# MSP430G2X52 register map
Vendor: msp430gen; File version: v0.4.0-16-g4f822b9
Registers are 8-bit, read-write, reset 0x0 unless marked. A register's access mark holds for its fields unless they carry their own. Offsets are from the block's base; lines under a group give offsets from that group; [hi:lo] are bit positions; {n}, {i} and the like mark numbered series; 'fields as' and 'values as' point back to an identical list; <NAME> marks a mode.

## Memory map
0x00000000 SPECIAL_FUNCTION
0x00000020 PORT_1_2
0x00000048 ADC10
0x00000052 SYSTEM_CLOCK
0x00000058 COMPARATOR_A
0x00000078 USI
0x00000120 WATCHDOG_TIMER
0x00000128 FLASH
0x0000012E TIMER0_A3 — Timer A3
0x000010C0 TLV_CALIBRATION_DATA
0x000010F8 CALIBRATION_DATA
0x0000FFE0 _INTERRUPTS

## Interrupts
2 PORT1 (_INTERRUPTS) — 0xFFE4 Port 1
3 PORT2 (_INTERRUPTS) — 0xFFE6 Port 2
4 USI (_INTERRUPTS) — 0xFFE8 USI
5 ADC10 (_INTERRUPTS) — 0xFFEA ADC10
8 TIMER0_A1 (_INTERRUPTS) — 0xFFF0 Timer0_A CC1, TA
9 TIMER0_A0 (_INTERRUPTS) — 0xFFF2 Timer0_A CC0
10 WDT (_INTERRUPTS) — 0xFFF4 Watchdog Timer
11 COMPARATORA (_INTERRUPTS) — 0xFFF6 Comparator A
14 NMI (_INTERRUPTS) — 0xFFFC Non-maskable

## SPECIAL_FUNCTION
Base 0x00000000
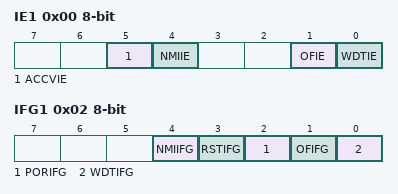
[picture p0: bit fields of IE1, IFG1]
0x00 IE1 — Interrupt Enable 1
  [5] ACCVIE — Flash Access Violation Interrupt Enable
  [4] NMIIE — NMI Interrupt Enable
  [1] OFIE — Osc. Fault Interrupt Enable
  [0] WDTIE — Watchdog Interrupt Enable
0x02 IFG1 — Interrupt Flag 1
  [4] NMIIFG — NMI Interrupt Flag
  [3] RSTIFG — Reset Interrupt Flag
  [2] PORIFG — Power On Interrupt Flag
  [1] OFIFG — Osc. Fault Interrupt Flag
  [0] WDTIFG — Watchdog Interrupt Flag

## PORT_1_2
Base 0x00000020
0x00 P1IN — Port 1 Input
  [n] P{n} (n=0..7)
  [7:0] P1IN — Port 1 Input register
0x01 P1OUT — Port 1 Output
  [n] P{n} (n=0..7)
  [7:0] P1OUT — Port 1 Output register
0x02 P1DIR — Port 1 Direction
  [n] P{n} (n=0..7)
  [7:0] P1DIR — Port 1 Direction register
0x03 P1IFG — Port 1 Interrupt Flag
  [n] P{n} (n=0..7)
  [7:0] P1IFG — Port 1 Interrupt Flag register
0x04 P1IES — Port 1 Interrupt Edge Select
  [n] P{n} (n=0..7)
  [7:0] P1IES — Port 1 Interrupt Edge Select register
0x05 P1IE — Port 1 Interrupt Enable
  [n] P{n} (n=0..7)
  [7:0] P1IE — Port 1 Interrupt Enable register
0x06 P1SEL — Port 1 Selection
  [n] P{n} (n=0..7)
  [7:0] P1SEL — Port 1 Selection register
0x07 P1REN — Port 1 Resistor Enable
  [n] P{n} (n=0..7)
  [7:0] P1REN — Port 1 Resistor Enable register
0x08 P2IN — Port 2 Input
  [n] P{n} (n=0..7)
  [7:0] P2IN — Port 2 Input register
0x09 P2OUT — Port 2 Output
  [n] P{n} (n=0..7)
  [7:0] P2OUT — Port 2 Output register
0x0A P2DIR — Port 2 Direction
  [n] P{n} (n=0..7)
  [7:0] P2DIR — Port 2 Direction register
0x0B P2IFG — Port 2 Interrupt Flag
  [n] P{n} (n=0..7)
  [7:0] P2IFG — Port 2 Interrupt Flag register
0x0C P2IES — Port 2 Interrupt Edge Select
  [n] P{n} (n=0..7)
  [7:0] P2IES — Port 2 Interrupt Edge Select register
0x0D P2IE — Port 2 Interrupt Enable
  [n] P{n} (n=0..7)
  [7:0] P2IE — Port 2 Interrupt Enable register
0x0E P2SEL — Port 2 Selection
  [n] P{n} (n=0..7)
  [7:0] P2SEL — Port 2 Selection register
0x0F P2REN — Port 2 Resistor Enable
  [n] P{n} (n=0..7)
  [7:0] P2REN — Port 2 Resistor Enable register
0x21 P1SEL2 — Port 1 Selection 2
  [n] P{n} (n=0..7)
  [7:0] P1SEL2 — Port 1 Selection register 2
0x22 P2SEL2 — Port 2 Selection 2
  [n] P{n} (n=0..7)
  [7:0] P2SEL2 — Port 2 Selection register 2

## ADC10
Base 0x00000048
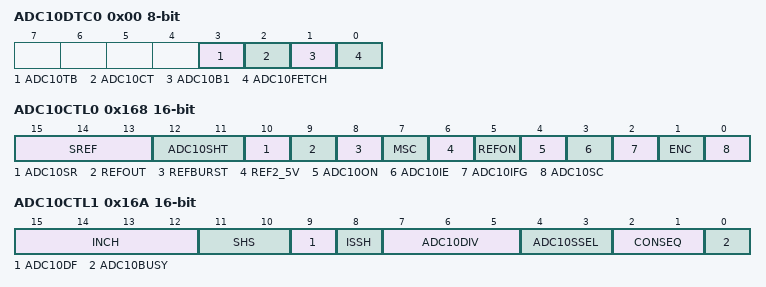
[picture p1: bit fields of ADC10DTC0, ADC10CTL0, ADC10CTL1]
0x00 ADC10DTC0 — ADC10 Data Transfer Control 0
  [3] ADC10TB — ADC10 two-block mode
  [2] ADC10CT — ADC10 continuous transfer
  [1] ADC10B1 — ADC10 block one
  [0] ADC10FETCH — This bit should normally be reset
0x01 ADC10DTC1 — ADC10 Data Transfer Control 1
  [7:0] ADC10DTC1 — ADC10 Data Transfer Control 1 register
0x02 ADC10AE0 — ADC10 Analog Enable 0
  [7:0] ADC10AE0 — ADC10 Analog Enable 0 register
0x168 ADC10CTL0 16-bit — ADC10 Control 0
  [15:13] SREF — ADC10 Reference Select Bit: 0
    0=VR+ = AVCC and VR- = AVSS; 1=VR+ = VREF+ and VR- = AVSS; 2=VR+ = VEREF+ and VR- = AVSS; 3=VR+ = VEREF+ and VR- = AVSS; 4=VR+ = AVCC and VR- = VREF-/VEREF-; 5=VR+ = VREF+ and VR- = VREF-/VEREF-; 6=VR+ = VEREF+ and VR- = VREF-/VEREF-; 7=VR+ = VEREF+ and VR- = VREF-/VEREF-
  [12:11] ADC10SHT — ADC10 Sample Hold Select Bit: 0
    0=4 x ADC10CLKs; 1=8 x ADC10CLKs; 2=16 x ADC10CLKs; 3=64 x ADC10CLKs
  [10] ADC10SR — ADC10 Sampling Rate 0:200ksps / 1:50ksps
  [9] REFOUT — ADC10 Enalbe output of Ref.
  [8] REFBURST — ADC10 Reference Burst Mode
  [7] MSC — ADC10 Multiple SampleConversion
  [6] REF2_5V — ADC10 Ref 0:1.5V / 1:2.5V
  [5] REFON — ADC10 Reference on
  [4] ADC10ON — ADC10 On/Enable
  [3] ADC10IE — ADC10 Interrupt Enalbe
  [2] ADC10IFG — ADC10 Interrupt Flag
  [1] ENC — ADC10 Enable Conversion
  [0] ADC10SC — ADC10 Start Conversion
0x16A ADC10CTL1 16-bit — ADC10 Control 1
  [15:12] INCH — ADC10 Input Channel Select Bit: 0
    {v}=Selects Channel {v} (v=0..15)
  [11:10] SHS — ADC10 Sample/Hold Source Bit: 0
    0=ADC10SC; 1=TA3 OUT1; 2=TA3 OUT0; 3=TA3 OUT2
  [9] ADC10DF — ADC10 Data Format 0:binary 1:2's complement
  [8] ISSH — ADC10 Invert Sample Hold Signal
  [7:5] ADC10DIV — ADC10 Clock Divider Select Bit: 0
    {v}=ADC10 Clock Divider Select {v} (v=0..7)
  [4:3] ADC10SSEL — ADC10 Clock Source Select Bit: 0
    0=ADC10OSC; 1=ACLK; 2=MCLK; 3=SMCLK
  [2:1] CONSEQ — ADC10 Conversion Sequence Select 0
    0=Single channel single conversion; 1=Sequence of channels; 2=Repeat single channel; 3=Repeat sequence of channels
  [0] ADC10BUSY
0x16C ADC10MEM 16-bit — ADC10 Memory
  [15:0] ADC10MEM — ADC10 Memory register
0x174 ADC10SA 16-bit — ADC10 Data Transfer Start Address
  [15:0] ADC10SA — ADC10 Data Transfer Start Address register
